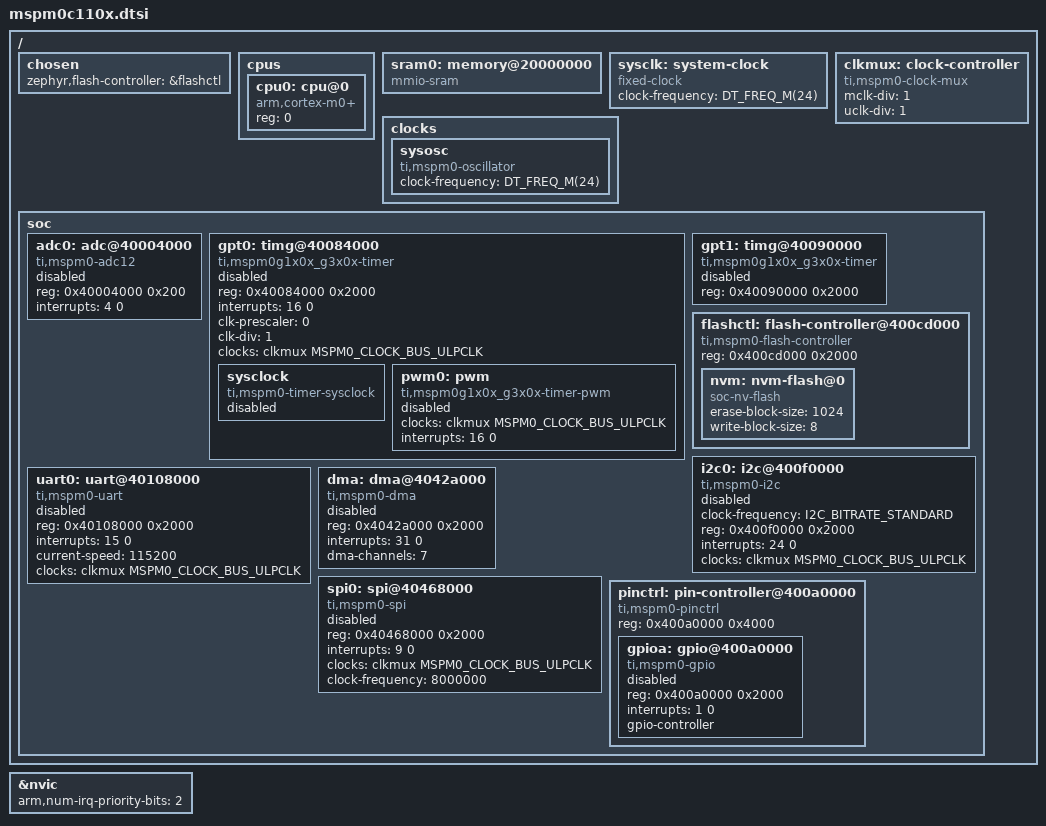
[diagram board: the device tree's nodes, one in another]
/* SPDX-License-Identifier: Apache-2.0 */

#include <arm/armv6-m.dtsi>
#include <zephyr/dt-bindings/gpio/gpio.h>
#include <zephyr/dt-bindings/i2c/i2c.h>
#include <zephyr/dt-bindings/clock/mspm0_clock.h>
#include <freq.h>

/ {
	chosen {
		zephyr,flash-controller = &flashctl;
	};

	cpus {
		#address-cells = <1>;
		#size-cells = <0>;

		cpu0: cpu@0 {
			device_type = "cpu";
			compatible = "arm,cortex-m0+";
			reg = <0>;
			#address-cells = <1>;
			#size-cells = <1>;
		};
	};

	sram0: memory@20000000 {
		compatible = "mmio-sram";
	};

	sysclk: system-clock {
		compatible = "fixed-clock";
		clock-frequency = <DT_FREQ_M(24)>;
		#clock-cells = <0>;
	};

	clkmux: clock-controller {
		compatible = "ti,mspm0-clock-mux";
		mclk-div = <1>;
		uclk-div = <1>;
		#clock-cells = <1>;
	};

	clocks: clocks {
		sysosc: sysosc {
			compatible = "ti,mspm0-oscillator";
			clock-frequency = <DT_FREQ_M(24)>;
			#clock-cells = <1>;
		};
	};

	soc {
		adc0: adc@40004000 {
			compatible = "ti,mspm0-adc12";
			reg = <0x40004000 0x200>;
			interrupts = <4 0>;
			status = "disabled";
			#io-channel-cells = <1>;
		};

		/* TIMG14 */
		gpt0: timg@40084000 {
			compatible = "ti,mspm0g1x0x_g3x0x-timer";
			reg = <0x40084000 0x2000>;
			interrupts = <16 0>;
			clk-prescaler = <0>;
			clk-div = <1>;
			clocks = <&clkmux MSPM0_CLOCK_BUS_ULPCLK>;
			status = "disabled";

			sysclock: sysclock {
				compatible = "ti,mspm0-timer-sysclock";
				status = "disabled";
			};

			pwm0: pwm {
				compatible = "ti,mspm0g1x0x_g3x0x-timer-pwm";
				clocks = <&clkmux MSPM0_CLOCK_BUS_ULPCLK>;
				interrupts = <16 0>;
				#pwm-cells = <3>;
				status = "disabled";
			};
		};

		/* TIMG8 */
		gpt1: timg@40090000 {
			compatible = "ti,mspm0g1x0x_g3x0x-timer";
			reg = <0x40090000 0x2000>;
			status = "disabled";
		};

		flashctl: flash-controller@400cd000 {
			compatible = "ti,mspm0-flash-controller";
			reg = <0x400cd000 0x2000>;
			#address-cells = <1>;
			#size-cells = <1>;

			nvm: nvm-flash@0 {
				compatible = "soc-nv-flash";
				erase-block-size = <1024>;
				write-block-size = <8>; /* 64-bit */
			};
		};

		i2c0: i2c@400f0000 {
			compatible = "ti,mspm0-i2c";
			clock-frequency = <I2C_BITRATE_STANDARD>;
			#address-cells = <1>;
			#size-cells = <0>;
			reg = <0x400f0000 0x2000>;
			interrupts = <24 0>;
			clocks = <&clkmux MSPM0_CLOCK_BUS_ULPCLK>;
			status = "disabled";
		};

		uart0: uart@40108000 {
			compatible = "ti,mspm0-uart";
			reg = <0x40108000 0x2000>;
			interrupts = <15 0>;
			current-speed = <115200>;
			clocks = <&clkmux MSPM0_CLOCK_BUS_ULPCLK>;
			status = "disabled";
		};

		dma: dma@4042a000 {
			compatible = "ti,mspm0-dma";
			reg = <0x4042a000 0x2000>;
			interrupts = <31 0>;
			dma-channels = <7>;
			#dma-cells = <2>;
			status = "disabled";
		};

		spi0: spi@40468000 {
			compatible = "ti,mspm0-spi";
			reg = <0x40468000 0x2000>;
			interrupts = <9 0>;
			clocks = <&clkmux MSPM0_CLOCK_BUS_ULPCLK>;
			clock-frequency = <8000000>;
			status = "disabled";
		};

		pinctrl: pin-controller@400a0000 {
			compatible = "ti,mspm0-pinctrl";
			#address-cells = <1>;
			#size-cells = <1>;
			reg = <0x400a0000 0x4000>;

			gpioa: gpio@400a0000 {
				compatible = "ti,mspm0-gpio";
				reg = <0x400a0000 0x2000>;
				interrupts = <1 0>;
				status = "disabled";
				gpio-controller;
				#gpio-cells = <2>;
			};
		};
	};
};

&nvic {
	arm,num-irq-priority-bits = <2>;
};
